AUTOSAR XML (schema 4-2-2)
package /AUTOLIV/SoftwareComponents/EcuMIf
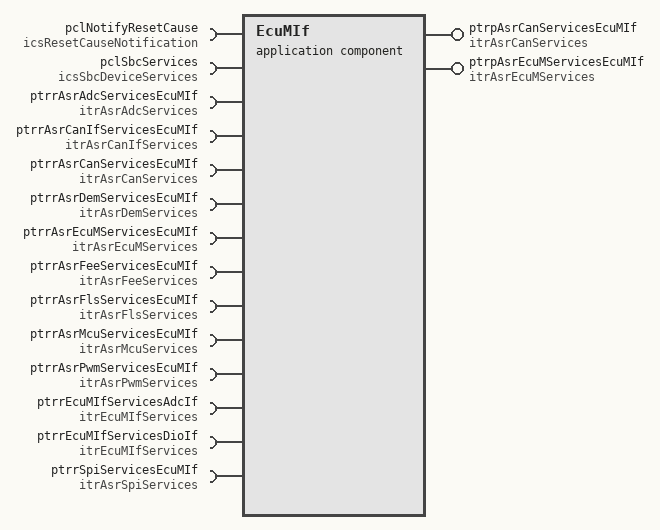
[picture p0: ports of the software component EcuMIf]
  application sw component type EcuMIf: category=BSW_System_Services
    require port pclNotifyResetCause: client-com-spec=NotifyResetCause, required-interface=icsResetCauseNotification  # # Architecture Element ID ARCH_SW_EcuMIf_pclNotifyResetCause_EcuM_AL_SwitchOff # Description - The interface shall be used to set notify the reset casuse in RCM module. # Data Flow ## Inputs: - {Reset Cause Notification Type} - {Reset Cause Status} # Linked Runnable - EcuM_AL_SwitchOff #Traceability ---------------------------------------------------------------------------------------------------------------------
    require port pclSbcServices: required-com-specs=[SBC_Reset, SBC_Shutdown, GetSbcStatus], required-interface=icsSbcDeviceServices  # # Architecture Element ID ARCH_SW_EcuMIf_pclSbcServices_EcuM_AL_Reset # Description - The interface shall be used to perform a SBC reset. # Data Flow ## Inputs: # Linked Runnable - EcuM_AL_Reset #Traceability --------------------------------------------------------------------------------------------------------------------- # Architecture Element ID ARCH_SW_EcuMIf_pclSbcServices_EcuM_AL_SwitchOff # Description - The interface shall be used to perform a SBC shutdown to cut off the uC power supply # Data Flow ## Inputs: # Linked Runnable - EcuM_AL_SwitchOff #Traceability ---------------------------------------------------------------------------------------------------------------------
    provide port ptrpAsrCanServicesEcuMIf: provided-interface=itrAsrCanServices  # # Architecture Element ID ARCH_SW_EcuMIf_ptrpAsrCanIfServicesEcuMIf_Can_CheckWakeup # Description - The Can_CheckWakeup runnable shall be called by the Autosar CanIf module to know what wakeup source needs to be checked # Data Flow ## Input - {Controller} - Can controller ID #Linked Runnable - Can_CheckWakeup # Traceability -----------------------------------------------------------------------------------------------------------------------------------
    provide port ptrpAsrEcuMServicesEcuMIf: provided-interface=itrAsrEcuMServices  # # Architecture Element ID ARCH_SW_EcuMIf_ptrpAsrEcuMServicesEcuMIf_EcuM_AL_DriverInitOne # Description - The EcuM_AL_DriverInitOne runnable shall be called by the Autosar EcuM at startup procedure to initializes all the EcuM configured modules. # Data Flow ## Outputs - {ConfigPtr} - Type for EcuM configuration #Linked Runnable - EcuM_AL_DriverInitOne # Traceability DOM_eCS_TF_P_280 ----------------------------------------------------------------------------------------------------------------------------------- # Architecture Element ID ARCH_SW_EcuMIf_ptrpAsrEcuMServicesEcuMIf_EcuM_DriverInitListOne # Description - The EcuM_DriverInitListOne runnable shall be called by the Autosar EcuM at startup procedure to initialize default list one: - Dem - Mcu - McuArchClock - Port - Can - Fls - Fee - Adc - AdcIf - Pwm - DioIf - Spi - Sbc # Data Flow #Linked Runnable - EcuM_DriverInitListOne # Traceability ----------------------------------------------------------------------------------------------------------------------------------- # Architecture Element ID ARCH_SW_EcuMIf_ptrpAsrEcuMServicesEcuMIf_EcuM_DeterminePbConfiguration # Description - The EcuM_DeterminePbConfiguration runnable shall be called by the Autosar EcuM at startup procedure to evaluate some condition, like port pin or NVRAM value, to determine which post-build configuration shall be used. # Data Flow #Linked Runnable - EcuM_DeterminePbConfiguration # Traceability ----------------------------------------------------------------------------------------------------------------------------------- # Architecture Element ID ARCH_SW_EcuMIf_ptrpAsrEcuMServicesEcuMIf_EcuM_AL_SetProgrammableInterrupts # Description - The EcuM_AL_SetProgrammableInterrupts runnable shall be called by the Autosar EcuM at startup phase and shall set the interrupts on ECUs with programmable interrupts. # Data Flow #Linked Runnable - EcuM_AL_SetProgrammableInterrupts # Traceability ----------------------------------------------------------------------------------------------------------------------------------- # Architecture Element ID ARCH_SW_EcuMIf_ptrpAsrEcuMServicesEcuMIf_EcuM_ErrorHook # Description - The EcuM_ErrorHook runnable shall be called by the Autosar EcuM to handle the production error ECUM_RAM_CHECK_FAILED when RAM Check fails on wakeup. # Data Flow #Input: - {reason} : Error hook reason #Linked Runnable - EcuM_ErrorHook # Traceability ----------------------------------------------------------------------------------------------------------------------------------- # Architecture Element ID ARCH_SW_EcuMIf_ptrpAsrEcuMServicesEcuMIf_EcuM_GenerateRamHash # Description - The EcuM_GenerateRamHash runnable shall be called by the Autosar EcuM for writing a RAM hash just before putting the ECU physically to sleep. # Data Flow #Linked Runnable - EcuM_GenerateRamHash # Traceability ----------------------------------------------------------------------------------------------------------------------------------- # Architecture Element ID ARCH_SW_EcuMIf_ptrpAsrEcuMServicesEcuMIf_EcuM_CheckRamHash # Description - The EcuM_CheckRamHash runnable shall be called by the Autosar EcuM to provide a RAM integrity test. # Data Flow #Output - {RamTestResult} #Linked Runnable - EcuM_CheckRamHash # Traceability ----------------------------------------------------------------------------------------------------------------------------------- # Architecture Element ID ARCH_SW_EcuMIf_ptrpAsrEcuMServicesEcuMIf_EcuM_OnGoOffOne # Description - The EcuM_OnGoOffOne runnable shall be called by the Autosar EcuM when ECU state manager module perform a power off or a reset depending on the selected shutdown target. # Data Flow #Linked Runnable - EcuM_OnGoOffOne # Traceability ----------------------------------------------------------------------------------------------------------------------------------- # Architecture Element ID ARCH_SW_EcuMIf_ptrpAsrEcuMServicesEcuMIf_EcuM_OnGoOffTwo # Description - The EcuM_OnGoOffTwo runnable shall be called by the Autosar EcuM when ECU state manager module perform a power off or a reset depending on the selected shutdown target but after EcuM_OnGoOffOne was executed # Data Flow #Linked Runnable - EcuM_OnGoOffTwo # Traceability ----------------------------------------------------------------------------------------------------------------------------------- # Architecture Element ID ARCH_SW_EcuMIf_ptrpAsrEcuMServicesEcuMIf_EcuM_AL_SwitchOff # Description - The EcuM_AL_SwitchOff runnable shall be called by the Autosar EcuM as the last activity in the OffPostOS Sequence. # Data Flow #Linked Runnable - EcuM_AL_SwitchOff # Traceability DOM_eCS_TF_P_219, DOM_eCS_TF_P_368, DOM_eCS_TF_P_369, DOM_eCS_TF_P_370 ----------------------------------------------------------------------------------------------------------------------------------- # Architecture Element ID ARCH_SW_EcuMIf_ptrpAsrEcuMServicesEcuMIf_EcuM_AL_Reset # Description - The EcuM_AL_Reset runnable shall be called by the Autosar EcuM when the shutdown target is RESET, and the shutdown procedure is made. # Data Flow #Input - {ResetType}: * ECUM_RESET_MCU - Perform Microcontroller reset via Mcu_PerformReset; * ECUM_RESET_WDG - Perform Watchdog reset via WdgM_PerformReset * ECUM_RESET_IO - Perform Reset by toggeling an I/O line #Linked Runnable - EcuM_AL_Reset # Traceability ----------------------------------------------------------------------------------------------------------------------------------- # Architecture Element ID ARCH_SW_EcuMIf_ptrpAsrEcuMServicesEcuMIf_EcuM_SleepActivity # Description - The EcuM_SleepActivity runnable shall be called by the Autosar EcuM in Poll sequence in a blocking loop at maximum frequency until a pending wakeup event is reported if the MCU is not halted # Data Flow #Linked Runnable - EcuM_SleepActivity # Traceability ----------------------------------------------------------------------------------------------------------------------------------- # Architecture Element ID ARCH_SW_EcuMIf_ptrpAsrEcuMServicesEcuMIf_EcuM_PreHalt # Description - The EcuM_PreHalt runnable shall be called by the Autosar EcuM during sleep state before to put the ECU in Halt State. # Data Flow #Linked Runnable - EcuM_PreHalt # Traceability ----------------------------------------------------------------------------------------------------------------------------------- # Architecture Element ID ARCH_SW_EcuMIf_ptrpAsrEcuMServicesEcuMIf_EcuM_PostHalt # Description - The EcuM_PostHalt runnable shall be called by the Autosar EcuM during sleep state after ECU exited Halt State # Data Flow #Linked Runnable - EcuM_PostHalt # Traceability ----------------------------------------------------------------------------------------------------------------------------------- # Architecture Element ID ARCH_SW_EcuMIf_ptrpAsrEcuMServicesEcuMIf_EcuM_StartWakeupSources # Description - The EcuM_StartWakeupSources runnable shall be called by the Autosar EcuM to start the pending wakeup sources # Data Flow #Input - {wakeupSource}: * ECUM_WKSOURCE_CAN - 32U; * ECUM_WKSOURCE_EXTERNAL_WDG - 16U * EcuM_ECUM_WKSOURCE_INTERNAL_WDG - 8U * EcuM_ECUM_WKSOURCE_INTERNAL_RESET - 4U * EcuM_ECUM_WKSOURCE_RESET - 2U * EcuM_ECUM_WKSOURCE_POWER - 1U #Linked Runnable - EcuM_StartWakeupSources # Traceability ----------------------------------------------------------------------------------------------------------------------------------- # Architecture Element ID ARCH_SW_EcuMIf_ptrpAsrEcuMServicesEcuMIf_EcuM_StopWakeupSources # Description - The EcuM_StopWakeupSources runnable shall be called by the Autosar EcuM to stop the pending wakeup sources # Data Flow #Input - {wakeupSource}: * ECUM_WKSOURCE_CAN - 32U; * ECUM_WKSOURCE_EXTERNAL_WDG - 16U * EcuM_ECUM_WKSOURCE_INTERNAL_WDG - 8U * EcuM_ECUM_WKSOURCE_INTERNAL_RESET - 4U * EcuM_ECUM_WKSOURCE_RESET - 2U * EcuM_ECUM_WKSOURCE_POWER - 1U #Linked Runnable - EcuM_StopWakeupSources # Traceability ----------------------------------------------------------------------------------------------------------------------------------- # Architecture Element ID ARCH_SW_EcuMIf_ptrpAsrEcuMServicesEcuMIf_EcuM_EnableWakeupSources # Description - The EcuM_EnableWakeupSources runnable shall be called by the Autosar EcuM to enable wakeup sources # Data Flow #Input - {wakeupSource}: * ECUM_WKSOURCE_CAN - 32U; * ECUM_WKSOURCE_EXTERNAL_WDG - 16U * EcuM_ECUM_WKSOURCE_INTERNAL_WDG - 8U * EcuM_ECUM_WKSOURCE_INTERNAL_RESET - 4U * EcuM_ECUM_WKSOURCE_RESET - 2U * EcuM_ECUM_WKSOURCE_POWER - 1U #Linked Runnable - EcuM_EnableWakeupSources # Traceability ----------------------------------------------------------------------------------------------------------------------------------- # Architecture Element ID ARCH_SW_EcuMIf_ptrpAsrEcuMServicesEcuMIf_EcuM_DisableWakeupSources # Description - The EcuM_DisableWakeupSources runnable shall be called by the Autosar EcuM to disable wakeup sources # Data Flow #Input - {wakeupSource}: * ECUM_WKSOURCE_CAN - 32U; * ECUM_WKSOURCE_EXTERNAL_WDG - 16U * EcuM_ECUM_WKSOURCE_INTERNAL_WDG - 8U * EcuM_ECUM_WKSOURCE_INTERNAL_RESET - 4U * EcuM_ECUM_WKSOURCE_RESET - 2U * EcuM_ECUM_WKSOURCE_POWER - 1U #Linked Runnable - EcuM_DisableWakeupSources # Traceability ----------------------------------------------------------------------------------------------------------------------------------- # Architecture Element ID ARCH_SW_EcuMIf_ptrpAsrEcuMServicesEcuMIf_EcuM_CheckValidation # Description - The EcuM_CheckValidation runnable shall be called by the Autosar EcuM to check for pending wakeup sources # Data Flow #Input - {wakeupSource}: * ECUM_WKSOURCE_CAN - 32U; * ECUM_WKSOURCE_EXTERNAL_WDG - 16U * EcuM_ECUM_WKSOURCE_INTERNAL_WDG - 8U * EcuM_ECUM_WKSOURCE_INTERNAL_RESET - 4U * EcuM_ECUM_WKSOURCE_RESET - 2U * EcuM_ECUM_WKSOURCE_POWER - 1U #Linked Runnable - EcuM_CheckValidation # Traceability DOM_eCS_TF_P_237 ----------------------------------------------------------------------------------------------------------------------------------- # Architecture Element ID ARCH_SW_EcuMIf_ptrpAsrEcuMServicesEcuMIf_EcuM_CheckWakeup # Description - The EcuM_CheckWakeup runnable shall be called by the Autosar EcuM to check all wakeup sources # Data Flow #Input - {wakeupSource}: * ECUM_WKSOURCE_CAN - 32U; * ECUM_WKSOURCE_EXTERNAL_WDG - 16U * EcuM_ECUM_WKSOURCE_INTERNAL_WDG - 8U * EcuM_ECUM_WKSOURCE_INTERNAL_RESET - 4U * EcuM_ECUM_WKSOURCE_RESET - 2U * EcuM_ECUM_WKSOURCE_POWER - 1U #Linked Runnable - EcuM_CheckWakeup # Traceability DOM_eCS_TF_P_237
    12 x require port:
      ptrrAsrAdcServicesEcuMIf: required-interface=itrAsrAdcServices  # # Architecture Element ID ARCH_SW_EcuMIf_ptrrAsrAdcServicesEcuMIf_EcuM_DriverInitListOne # Description - The Adc_Init runnable shall be called in the EcuM_DriverInitListOne runnable in order to initialize the ADC module # Data Flow #Input # Linked Runnable - EcuM_DriverInitListOne #Traceability --------------------------------------------------------------------------------------------------------------------------------------------------
      ptrrAsrCanIfServicesEcuMIf: required-interface=itrAsrCanIfServices  # # Architecture Element ID ARCH_SW_EcuMIf_ptrrAsrCanIfServicesEcuMIf_CanIf_SetControllerMode_EcuM_StartWakeupSources # Description - The CanIf_SetControllerMode runnable shall be called in the EcuM_StartWakeupSources runnable in order to set the CAN Controller mode. # Data Flow #Input - {ControllerId} - {ControllerMode} # Linked Runnable - EcuM_StartWakeupSources #Traceability -------------------------------------------------------------------------------------------------------------------------------------------------- # Architecture Element ID ARCH_SW_EcuMIf_ptrrAsrCanIfServicesEcuMIf_CanIf_SetControllerMode_EcuM_StopWakeupSources # Description - The CanIf_SetControllerMode runnable shall be called in the EcuM_StopWakeupSources runnable in order to set the CAN Controller mode. # Data Flow #Input - {ControllerId} - {ControllerMode} # Linked Runnable - EcuM_StopWakeupSources #Traceability -------------------------------------------------------------------------------------------------------------------------------------------------- # Architecture Element ID ARCH_SW_EcuMIf_ptrrAsrCanIfServicesEcuMIf_CanIf_CheckValidation_EcuM_CheckValidation # Description - The CanIf_CheckValidation runnable shall be called in the EcuM_CheckValidation runnable in order to start wakeup validation procedure # Data Flow #Input - {ControllerId} - {ControllerMode} # Linked Runnable - EcuM_CheckValidation #Traceability
      ptrrAsrCanServicesEcuMIf: required-interface=itrAsrCanServices  # # Architecture Element ID ARCH_SW_EcuMIf_ptrrAsrCanServicesEcuMIf_EcuM_DriverInitListOne # Description - The Can_Init runnable shall be called in the EcuM_DriverInitListOne runnable in order to initialize the Can module # Data Flow #Input # Linked Runnable - EcuM_DriverInitListOne #Traceability --------------------------------------------------------------------------------------------------------------------------------------------------
      ptrrAsrDemServicesEcuMIf: required-interface=itrAsrDemServices  # # Architecture Element ID ARCH_SW_EcuMIf_ptrrAsrDemServicesEcuMIf_EcuM_DriverInitListOne # Description - The Dem_PreInit runnable shall be called in the EcuM_DriverInitListOne runnable in order to initialize the Dem module # Data Flow #Input # Linked Runnable - EcuM_DriverInitListOne #Traceability --------------------------------------------------------------------------------------------------------------------------------------------------
      ptrrAsrEcuMServicesEcuMIf: required-interface=itrAsrEcuMServices  # # Architecture Element ID ARCH_SW_EcuMIf_ptrrAsrEcuMIfServicesEcuMIf_EcuM_DefaultInitListOne # Description - The EcuM_DefaultInitListOne runnable shall be called in the EcuM_DriverInitListOne runnable in order to initialize list one with modules. # Data Flow # Linked Runnable - EcuM_DriverInitListOne #Traceability
      ptrrAsrFeeServicesEcuMIf: required-interface=itrAsrFeeServices  # # Architecture Element ID ARCH_SW_EcuMIf_ptrrAsrFeeServicesEcuMIf_EcuM_DriverInitListOne # Description - The Fee_Init runnable shall be called in the EcuM_DriverInitListOne runnable in order to initialize the Fee module # Data Flow #Input # Linked Runnable - EcuM_DriverInitListOne #Traceability --------------------------------------------------------------------------------------------------------------------------------------------------
      ptrrAsrFlsServicesEcuMIf: required-interface=itrAsrFlsServices  # # Architecture Element ID ARCH_SW_EcuMIf_ptrrAsrFlsServicesEcuMIf_EcuM_DriverInitListOne # Description - The Fls_Init runnable shall be called in the EcuM_DriverInitListOne runnable in order to initialize the Fls module # Data Flow #Input # Linked Runnable - EcuM_DriverInitListOne #Traceability --------------------------------------------------------------------------------------------------------------------------------------------------
      ptrrAsrMcuServicesEcuMIf: required-interface=itrAsrMcuServices  # # Architecture Element ID ARCH_SW_EcuMIf_ptrrAsrMcuServicesEcuMIf_Mcu_PerformReset_EcuM_AL_Reset # Description - The Mcu_PerformReset runnable shall be called in the EcuM_AL_Reset runnable in order to reset de MCU. # Data Flow # Linked Runnable - EcuM_AL_Reset #Traceability -------------------------------------------------------------------------------------------------------------------------------------------------- # Architecture Element ID ARCH_SW_EcuMIf_ptrrAsrMcuServicesEcuMIf_EcuM_DriverInitListOne # Description - The Mcu_Init runnable shall be called in the EcuM_DriverInitListOne runnable in order to initialize the Mcu module # Data Flow #Input # Linked Runnable - EcuM_DriverInitListOne #Traceability --------------------------------------------------------------------------------------------------------------------------------------------------
      ptrrAsrPwmServicesEcuMIf: required-interface=itrAsrPwmServices  # # Architecture Element ID ARCH_SW_EcuMIf_ptrrAsrPwmServicesEcuMIf_EcuM_DriverInitListOne # Description - The Pwm_Init runnable shall be called in the EcuM_DriverInitListOne runnable in order to initialize the Pwm module # Data Flow #Input # Linked Runnable - EcuM_DriverInitListOne #Traceability --------------------------------------------------------------------------------------------------------------------------------------------------
      ptrrEcuMIfServicesAdcIf: required-interface=itrEcuMIfServices  # # Architecture Element ID ARCH_SW_EcuMIf_ptrpEcuMIfServicesAdcIf_EcuM_DriverInitListOne # Description - The AdcIf_Calib runnable shall be called in the EcuM_DriverInitListOne runnable in order to initialize AdcIf module # Data Flow # Linked Runnable - EcuM_DriverInitListOne #Traceability
      ptrrEcuMIfServicesDioIf: required-interface=itrEcuMIfServices  # # Architecture Element ID ARCH_SW_EcuMIf_ptrpEcuMIfServicesDioIf_EcuM_DriverInitListOne # Description - The DioIf_Init runnable shall be called in the EcuM_DriverInitListOne runnable in order to initialize DioIf module # Data Flow # Linked Runnable - EcuM_DriverInitListOne #Traceability
      ptrrSpiServicesEcuMIf: required-interface=itrAsrSpiServices  # # Architecture Element ID ARCH_SW_EcuMIf_ptrrSpiServicesEcuMIf_EcuM_DriverInitListOne # Description - The Spi_Init runnable shall be called in the EcuM_DriverInitListOne runnable in order to initialize the Spi module # Data Flow #Output {ConfigPtr} - Specifies the pointer to the configuration set # Linked Runnable - EcuM_DriverInitListOne #Traceability
